# STM32U5F9xx register map
File version: 1.0
Registers are 32-bit, read-write, reset 0x0 unless marked. A register's access mark holds for its fields unless they carry their own. Offsets are from the block's base; [hi:lo] are bit positions; 'fields as' and 'values as' point back to an identical list.

## LTDC — LCD-TFT Display Controller
Base 0x40016800
Same registers: LTDC_S 0x50016800
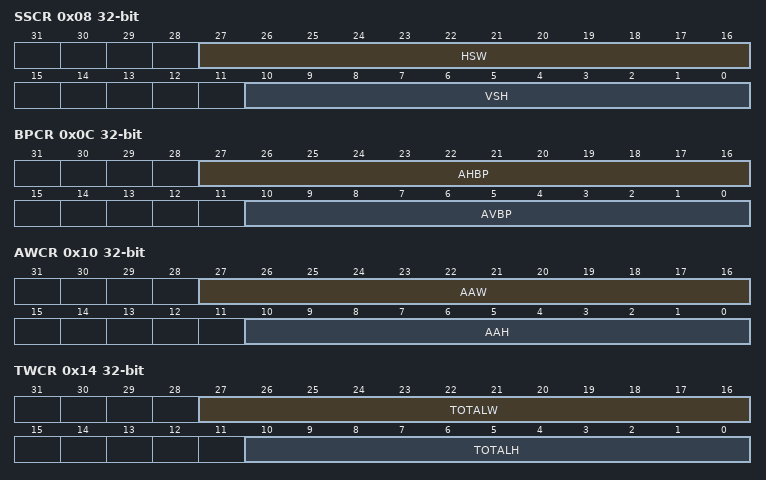
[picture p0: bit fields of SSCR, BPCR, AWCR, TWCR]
0x08 SSCR — LTDC Synchronization Size Configuration Register
  [27:16] HSW — Horizontal Synchronization Width
  [10:0] VSH — Vertical Synchronization Height
0x0C BPCR — LTDC Back Porch Configuration Register
  [27:16] AHBP — Accumulated Horizontal Back Porch
  [10:0] AVBP — Accumulated Vertical Back Porch
0x10 AWCR — LTDC Active Width Configuration Register
  [27:16] AAW — Accumulated Active Width
  [10:0] AAH — Accumulated Active height
0x14 TWCR — LTDC Total Width Configuration Register
  [27:16] TOTALW — Total Width
  [10:0] TOTALH — Total Height
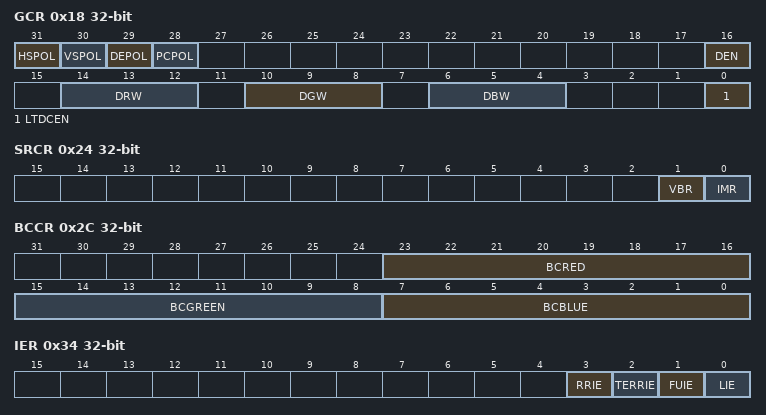
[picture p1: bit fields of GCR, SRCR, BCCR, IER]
0x18 GCR — LTDC Global Control Register
  [31] HSPOL — Horizontal Synchronization Polarity
  [30] VSPOL — Vertical Synchronization Polarity
  [29] DEPOL — Data Enable Polarity
  [28] PCPOL — Pixel Clock Polarity
  [16] DEN — Dither Enable
  [14:12] DRW — Dither Red Width
  [10:8] DGW — Dither Green Width
  [6:4] DBW — Dither Blue Width
  [0] LTDCEN — LCD-TFT controller enable bit
0x24 SRCR — LTDC Shadow Reload Configuration Register
  [1] VBR — Vertical Blanking Reload
  [0] IMR — Immediate Reload
0x2C BCCR — LTDC Background Color Configuration Register
  [23:16] BCRED — Background Red value
  [15:8] BCGREEN — Background Green value
  [7:0] BCBLUE — Background Blue value
0x34 IER — LTDC Interrupt Enable Register
  [3] RRIE — Register Reload interrupt enable
  [2] TERRIE — Transfer Error Interrupt Enable
  [1] FUIE — FIFO Underrun Interrupt Enable
  [0] LIE — Line Interrupt Enable
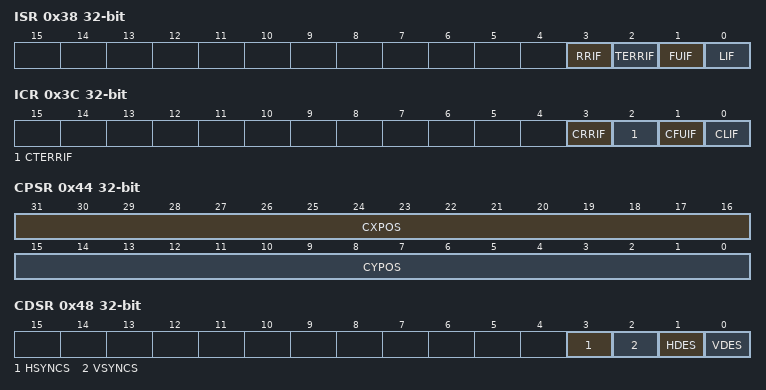
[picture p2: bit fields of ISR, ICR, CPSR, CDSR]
0x38 ISR — LTDC Interrupt Status Register
  [3] RRIF — Register Reload interrupt Flag
  [2] TERRIF — Transfer Error Interrupt Flag
  [1] FUIF — FIFO Underrun Interrupt Flag
  [0] LIF — Line Interrupt Flag
0x3C ICR — LTDC Interrupt Clear Register
  [3] CRRIF — Clears Register Reload interrupt Flag
  [2] CTERRIF — Clears the Transfer Error Interrupt Flag
  [1] CFUIF — Clears the FIFO Underrun Interrupt Flag
  [0] CLIF — Clears the Line Interrupt Flag
0x40 LIPCR — LTDC Line Interrupt Position Configuration Register
  [10:0] LIPOS — Line Interrupt Position
0x44 CPSR — LTDC Current Position Status Register
  [31:16] CXPOS — Current X Position
  [15:0] CYPOS — Current Y Position
0x48 CDSR — LTDC Current Display Status Register
  [3] HSYNCS — Horizontal Synchronization Status
  [2] VSYNCS — Vertical Synchronization Status
  [1] HDES — Horizontal Data Enable Status
  [0] VDES — Vertical Data Enable Status
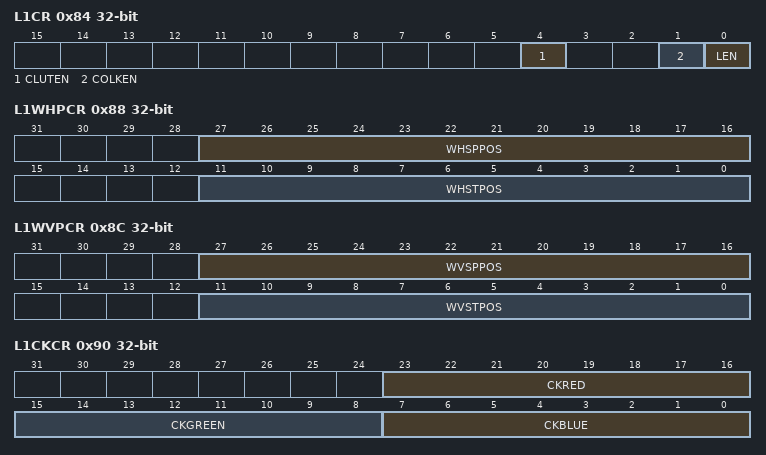
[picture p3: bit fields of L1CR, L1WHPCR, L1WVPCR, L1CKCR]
0x84 L1CR — LTDC Layerx Control Register
  [4] CLUTEN — Color Lockup Table Enable
  [1] COLKEN — Color Keying Enable
  [0] LEN — Layer Enable
0x88 L1WHPCR — LTDC Layerx Window Horizontal Position Configuration Register
  [27:16] WHSPPOS — Window Horizontal Stop Position
  [11:0] WHSTPOS — Window Horizontal Start Position
0x8C L1WVPCR — LTDC Layerx Window Vertical Position Configuration Register
  [27:16] WVSPPOS — Window Vertical Stop Position
  [11:0] WVSTPOS — Window Vertical Start Position
0x90 L1CKCR — LTDC Layerx Color Keying Configuration Register
  [23:16] CKRED — Color Key Red value
  [15:8] CKGREEN — Color Key Green value
  [7:0] CKBLUE — Color Key Blue value
0x94 L1PFCR — LTDC Layerx Pixel Format Configuration Register
  [2:0] PF — Pixel Format
0x98 L1CACR — LTDC Layerx Constant Alpha Configuration Register
  [7:0] CONSTA — Constant Alpha
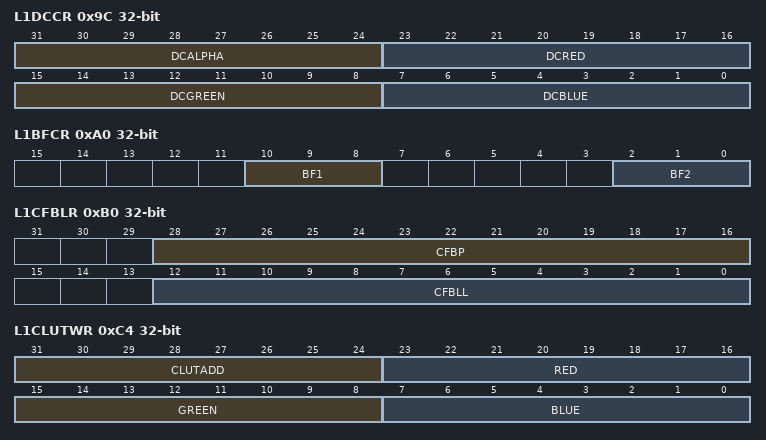
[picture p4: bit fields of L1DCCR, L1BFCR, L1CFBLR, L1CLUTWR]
0x9C L1DCCR — LTDC Layerx Default Color Configuration Register
  [31:24] DCALPHA — Default Color Alpha
  [23:16] DCRED — Default Color Red
  [15:8] DCGREEN — Default Color Green
  [7:0] DCBLUE — Default Color Blue
0xA0 L1BFCR — LTDC Layerx Blending Factors Configuration Register
  [10:8] BF1 — Blending Factor 1
  [2:0] BF2 — Blending Factor 2
0xAC L1CFBAR — LTDC Layerx Color Frame Buffer Address Register
  [31:0] CFBADD — Color Frame Buffer Start Address
0xB0 L1CFBLR — LTDC Layerx Color Frame Buffer Length Register
  [28:16] CFBP — Color Frame Buffer Pitch in bytes
  [12:0] CFBLL — Color Frame Buffer Line Length
0xB4 L1CFBLNR — LTDC Layerx ColorFrame Buffer Line Number Register
  [10:0] CFBLNBR — Frame Buffer Line Number
0xC4 L1CLUTWR — LTDC Layerx CLUT Write Register
  [31:24] CLUTADD — CLUT address
  [23:16] RED — Red value
  [15:8] GREEN — Green value
  [7:0] BLUE — Blue value
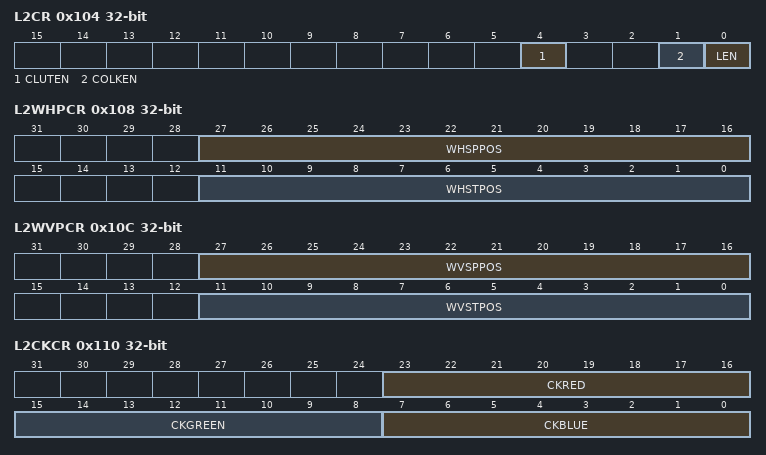
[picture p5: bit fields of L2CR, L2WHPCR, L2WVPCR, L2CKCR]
0x104 L2CR — LTDC Layerx Control Register
  fields as L1CR
0x108 L2WHPCR — LTDC Layerx Window Horizontal Position Configuration Register
  fields as L1WHPCR
0x10C L2WVPCR — LTDC Layerx Window Vertical Position Configuration Register
  fields as L1WVPCR
0x110 L2CKCR — LTDC Layerx Color Keying Configuration Register
  fields as L1CKCR
0x114 L2PFCR — LTDC Layerx Pixel Format Configuration Register
  [2:0] PF — Pixel Format
0x118 L2CACR — LTDC Layerx Constant Alpha Configuration Register
  [7:0] CONSTA — Constant Alpha
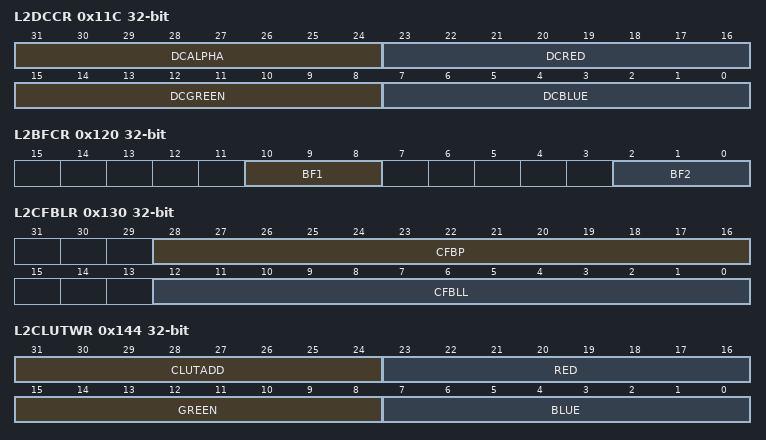
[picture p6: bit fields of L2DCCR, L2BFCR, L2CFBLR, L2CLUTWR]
0x11C L2DCCR — LTDC Layerx Default Color Configuration Register
  fields as L1DCCR
0x120 L2BFCR — LTDC Layerx Blending Factors Configuration Register
  [10:8] BF1 — Blending Factor 1
  [2:0] BF2 — Blending Factor 2
0x12C L2CFBAR — LTDC Layerx Color Frame Buffer Address Register
  [31:0] CFBADD — Color Frame Buffer Start Address
0x130 L2CFBLR — LTDC Layerx Color Frame Buffer Length Register
  fields as L1CFBLR
0x134 L2CFBLNR — LTDC Layerx ColorFrame Buffer Line Number Register
  [10:0] CFBLNBR — Frame Buffer Line Number
0x144 L2CLUTWR — LTDC Layerx CLUT Write Register
  fields as L1CLUTWR
